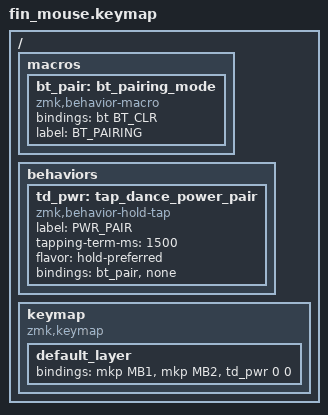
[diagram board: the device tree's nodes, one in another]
#include <behaviors.dtsi>
#include <dt-bindings/zmk/keys.h>
#include <dt-bindings/zmk/bt.h>
#include <dt-bindings/zmk/mouse.h>
#include <dt-bindings/zmk/outputs.h>

/ {
    macros {
        bt_pair: bt_pairing_mode {
            compatible = "zmk,behavior-macro";
            #binding-cells = <0>;
            bindings = <&bt BT_CLR>;
            label = "BT_PAIRING";
        };
    };

    behaviors {
        td_pwr: tap_dance_power_pair {
            compatible = "zmk,behavior-hold-tap";
            label = "PWR_PAIR";
            #binding-cells = <2>;
            tapping-term-ms = <1500>;
            flavor = "hold-preferred";
            bindings = <&bt_pair>, <&none>;
        };
    };

    keymap {
        compatible = "zmk,keymap";

        default_layer {
            bindings = <
                &mkp MB1
                &mkp MB2
                &td_pwr 0 0
            >;
        };
    };
};
